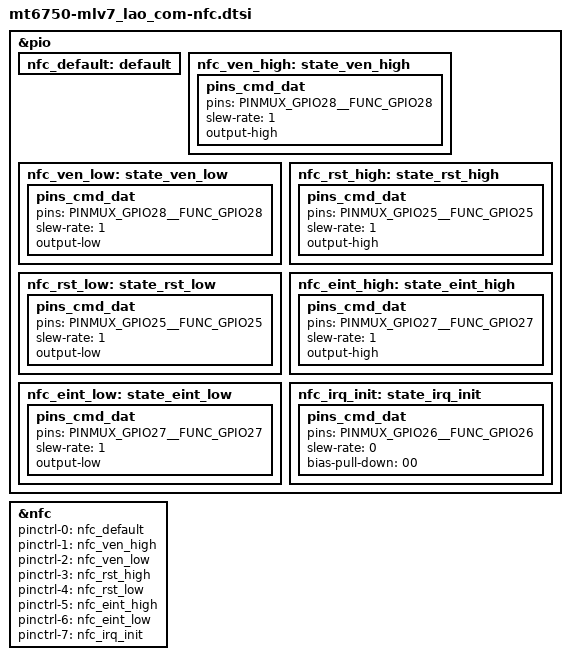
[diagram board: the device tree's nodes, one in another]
/*
 * LG Electronics LS7 nfc device tree source
 *
 * Copyright (c) 2017 LG Electronics Co., Ltd.
 *              http://www.lge.com
 *
 */

/* NFC GPIO standardization */
&pio {
	nfc_default: default {

	};

	nfc_ven_high: state_ven_high {
		pins_cmd_dat {
			pins = <PINMUX_GPIO28__FUNC_GPIO28>;
			slew-rate = <1>;
			output-high;
		};
	};

	nfc_ven_low: state_ven_low {
		pins_cmd_dat {
			pins = <PINMUX_GPIO28__FUNC_GPIO28>;
			slew-rate = <1>;
			output-low;
		};
	};

	nfc_rst_high: state_rst_high {
		pins_cmd_dat {
			pins = <PINMUX_GPIO25__FUNC_GPIO25>;
			slew-rate = <1>;
			output-high;
		};
	};

	nfc_rst_low: state_rst_low {
		pins_cmd_dat {
			pins = <PINMUX_GPIO25__FUNC_GPIO25>;
			slew-rate = <1>;
			output-low;
		};
	};

	nfc_eint_high: state_eint_high {
		pins_cmd_dat {
			pins = <PINMUX_GPIO27__FUNC_GPIO27>;
			slew-rate = <1>;
			output-high;
		};
	};

	nfc_eint_low: state_eint_low {
		pins_cmd_dat {
			pins = <PINMUX_GPIO27__FUNC_GPIO27>;
			slew-rate = <1>;
			output-low;
		};
	};

	nfc_irq_init: state_irq_init {
		pins_cmd_dat {
			pins = <PINMUX_GPIO26__FUNC_GPIO26>;
			slew-rate = <0>;
			bias-pull-down = <00>;
		};
	};
};

&nfc {
	pinctrl-names = "default", "ven_high", "ven_low", "rst_high", "rst_low", "eint_high", "eint_low", "irq_init";
	pinctrl-0 = <&nfc_default>;
	pinctrl-1 = <&nfc_ven_high>;
	pinctrl-2 = <&nfc_ven_low>;
	pinctrl-3 = <&nfc_rst_high>;
	pinctrl-4 = <&nfc_rst_low>;
	pinctrl-5 = <&nfc_eint_high>;
	pinctrl-6 = <&nfc_eint_low>;
	pinctrl-7 = <&nfc_irq_init>;
	status = "okay";
};
/* NFC end */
